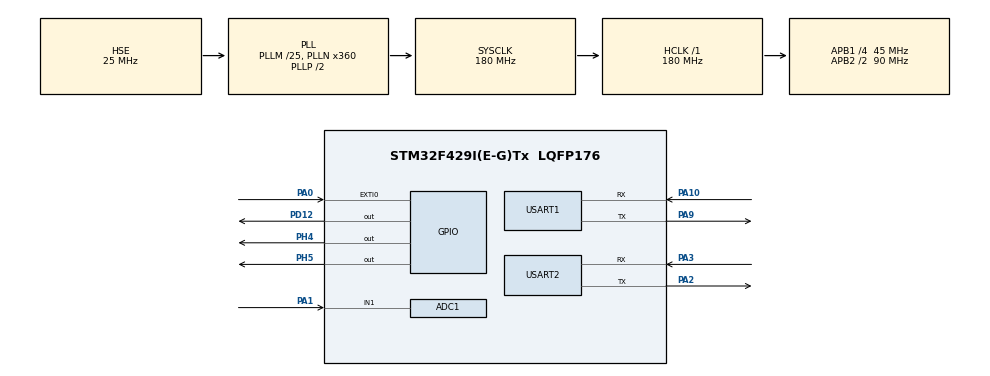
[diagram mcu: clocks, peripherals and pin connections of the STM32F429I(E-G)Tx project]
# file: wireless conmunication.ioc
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ADC1.Channel-0\#ChannelRegularConversion=ADC_CHANNEL_1
ADC1.ContinuousConvMode=ENABLE
ADC1.DataAlign=ADC_DATAALIGN_RIGHT
ADC1.InjNumberOfConversion=0
ADC1.NbrOfConversion=1
ADC1.NbrOfConversionFlag=1
ADC1.Rank-0\#ChannelRegularConversion=1
ADC1.SamplingTime-0\#ChannelRegularConversion=ADC_SAMPLETIME_480CYCLES
ADC1.master=1
Mcu.Family=STM32F4
Mcu.Name=STM32F429I(E-G)Tx
Mcu.Package=LQFP176
NVIC.EXTI0_IRQn=true\:0\:0\:false\:false\:true\:true\:true
NVIC.PriorityGroup=NVIC_PRIORITYGROUP_2
NVIC.TIM2_IRQn=true\:0\:0\:false\:false\:true\:true\:true
NVIC.TIM6_DAC_IRQn=true\:0\:0\:false\:false\:true\:true\:true
NVIC.USART1_IRQn=true\:0\:0\:false\:false\:true\:true\:true
NVIC.USART2_IRQn=true\:0\:0\:false\:false\:true\:true\:true
PA0/WKUP.GPIO_ModeDefaultEXTI=GPIO_MODE_IT_RISING
PA0/WKUP.GPIO_PuPd=GPIO_PULLDOWN
PA0/WKUP.Signal=GPXTI0
PA1.Signal=ADCx_IN1
PA10.Mode=Asynchronous
PA10.Signal=USART1_RX
PA13.Mode=JTAG_5_pins
PA13.Signal=SYS_JTMS-SWDIO
PA14.Mode=JTAG_5_pins
PA14.Signal=SYS_JTCK-SWCLK
PA15.Mode=JTAG_5_pins
PA15.Signal=SYS_JTDI
PA2.Mode=Asynchronous
PA2.Signal=USART2_TX
PA3.Mode=Asynchronous
PA3.Signal=USART2_RX
PA9.Mode=Asynchronous
PA9.Signal=USART1_TX
PB3.Mode=JTAG_5_pins
PB3.Signal=SYS_JTDO-SWO
PB4.Mode=JTAG_5_pins
PB4.Signal=SYS_JTRST
PD12.GPIO_PuPd=GPIO_NOPULL
PD12.GPIO_Speed=GPIO_SPEED_FREQ_MEDIUM
PD12.PinState=GPIO_PIN_SET
PD12.Signal=GPIO_Output
PH0/OSC_IN.Mode=HSE-External-Oscillator
PH0/OSC_IN.Signal=RCC_OSC_IN
PH1/OSC_OUT.Mode=HSE-External-Oscillator
PH1/OSC_OUT.Signal=RCC_OSC_OUT
PH4.GPIO_ModeDefaultOutputPP=GPIO_MODE_OUTPUT_OD
PH4.GPIO_PuPd=GPIO_PULLUP
PH4.GPIO_Speed=GPIO_SPEED_FREQ_HIGH
PH4.PinState=GPIO_PIN_SET
PH4.Signal=GPIO_Output
PH5.GPIO_ModeDefaultOutputPP=GPIO_MODE_OUTPUT_OD
PH5.GPIO_PuPd=GPIO_PULLUP
PH5.GPIO_Speed=GPIO_SPEED_FREQ_HIGH
PH5.PinState=GPIO_PIN_SET
PH5.Signal=GPIO_Output
ProjectManager.HeapSize=0x200
ProjectManager.StackSize=0x400
ProjectManager.TargetToolchain=MDK-ARM V5
RCC.48MHZClocksFreq_Value=90000000
RCC.AHBFreq_Value=180000000
RCC.APB1CLKDivider=RCC_HCLK_DIV4
RCC.APB1Freq_Value=45000000
RCC.APB1TimFreq_Value=90000000
RCC.APB2CLKDivider=RCC_HCLK_DIV2
RCC.APB2Freq_Value=90000000
RCC.APB2TimFreq_Value=180000000
RCC.CortexFreq_Value=180000000
RCC.HCLKFreq_Value=180000000
RCC.HSE_VALUE=25000000
RCC.HSI_VALUE=16000000
RCC.LSE_VALUE=32768
RCC.PLLM=25
RCC.PLLN=360
RCC.PLLSourceVirtual=RCC_PLLSOURCE_HSE
RCC.SYSCLKFreq_VALUE=180000000
RCC.SYSCLKSource=RCC_SYSCLKSOURCE_PLLCLK
RCC.VCOOutputFreq_Value=360000000
SH.ADCx_IN1.0=ADC1_IN1,IN1
TIM2.AutoReloadPreload=TIM_AUTORELOAD_PRELOAD_ENABLE
TIM2.Period=10000000
TIM2.Prescaler=90-1
TIM6.AutoReloadPreload=TIM_AUTORELOAD_PRELOAD_ENABLE
TIM6.Period=10000
TIM6.Prescaler=9000-1
USART1.VirtualMode=VM_ASYNC
USART2.VirtualMode=VM_ASYNC
VP_TIM2_VS_ClockSourceINT.Mode=Internal
VP_TIM6_VS_ClockSourceINT.Mode=Enable_Timer
board=custom

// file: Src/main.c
/* USER CODE BEGIN Header */
/**
  ******************************************************************************
  * @file           : main.c
  * @brief          : Main program body
  ******************************************************************************
  * @attention
  *
  * <h2><center>&copy; Copyright (c) 2021 STMicroelectronics.
  * All rights reserved.</center></h2>
  *
  * This software component is licensed by ST under BSD 3-Clause license,
  * the "License"; You may not use this file except in compliance with the
  * License. You may obtain a copy of the License at:
  *                        opensource.org/licenses/BSD-3-Clause
  *
  ******************************************************************************
  */
/* USER CODE END Header */
#include "main.h"
#include "adc.h"
#include "tim.h"
#include "usart.h"
#include "gpio.h"

/* USER CODE BEGIN Includes */
#include "delay.h"
#include "sys.h"
#include "iic.h"
#include "oled.h"
#include "esp8266.h"
/* USER CODE END Includes */

/* USER CODE BEGIN PV */
extern char press_data[5];
/* USER CODE END PV */

void SystemClock_Config(void);

int main(void)
{

  /* MCU Configuration--------------------------------------------------------*/

  /* Reset of all peripherals, Initializes the Flash interface and the Systick. */
  HAL_Init();

  /* Configure the system clock */
  SystemClock_Config();

  /* USER CODE BEGIN SysInit */
	delay_init();
  /* USER CODE END SysInit */

  /* Initialize all configured peripherals */
  MX_GPIO_Init();
  MX_USART1_UART_Init();
  MX_TIM2_Init();
  MX_TIM6_Init();
  MX_USART2_UART_Init();
  MX_ADC1_Init();
  /* USER CODE BEGIN 2 */
	IIC_Init();
	OLED_Init();
	atk_8266_quit_trans();
	esp8266_init();
  /* USER CODE END 2 */

  /* Infinite loop */
  while (1)
  {

  }
}

void SystemClock_Config(void)
{
  RCC_OscInitTypeDef RCC_OscInitStruct = {0};
  RCC_ClkInitTypeDef RCC_ClkInitStruct = {0};

  /** Configure the main internal regulator output voltage
  */
  __HAL_RCC_PWR_CLK_ENABLE();
  __HAL_PWR_VOLTAGESCALING_CONFIG(PWR_REGULATOR_VOLTAGE_SCALE1);
  /** Initializes the RCC Oscillators according to the specified parameters
  * in the RCC_OscInitTypeDef structure.
  */
  RCC_OscInitStruct.OscillatorType = RCC_OSCILLATORTYPE_HSE;
  RCC_OscInitStruct.HSEState = RCC_HSE_ON;
  RCC_OscInitStruct.PLL.PLLState = RCC_PLL_ON;
  RCC_OscInitStruct.PLL.PLLSource = RCC_PLLSOURCE_HSE;
  RCC_OscInitStruct.PLL.PLLM = 25;
  RCC_OscInitStruct.PLL.PLLN = 360;
  RCC_OscInitStruct.PLL.PLLP = RCC_PLLP_DIV2;
  RCC_OscInitStruct.PLL.PLLQ = 4;
  if (HAL_RCC_OscConfig(&RCC_OscInitStruct) != HAL_OK)
  {
    Error_Handler();
  }
  /** Activate the Over-Drive mode
  */
  if (HAL_PWREx_EnableOverDrive() != HAL_OK)
  {
    Error_Handler();
  }
  /** Initializes the CPU, AHB and APB buses clocks
  */
  RCC_ClkInitStruct.ClockType = RCC_CLOCKTYPE_HCLK|RCC_CLOCKTYPE_SYSCLK
                              |RCC_CLOCKTYPE_PCLK1|RCC_CLOCKTYPE_PCLK2;
  RCC_ClkInitStruct.SYSCLKSource = RCC_SYSCLKSOURCE_PLLCLK;
  RCC_ClkInitStruct.AHBCLKDivider = RCC_SYSCLK_DIV1;
  RCC_ClkInitStruct.APB1CLKDivider = RCC_HCLK_DIV4;
  RCC_ClkInitStruct.APB2CLKDivider = RCC_HCLK_DIV2;

  if (HAL_RCC_ClockConfig(&RCC_ClkInitStruct, FLASH_LATENCY_5) != HAL_OK)
  {
    Error_Handler();
  }
}

void Error_Handler(void)
{
  __disable_irq();
  while (1)
  {
  }
}

/************************ (C) COPYRIGHT STMicroelectronics *****END OF FILE****/
